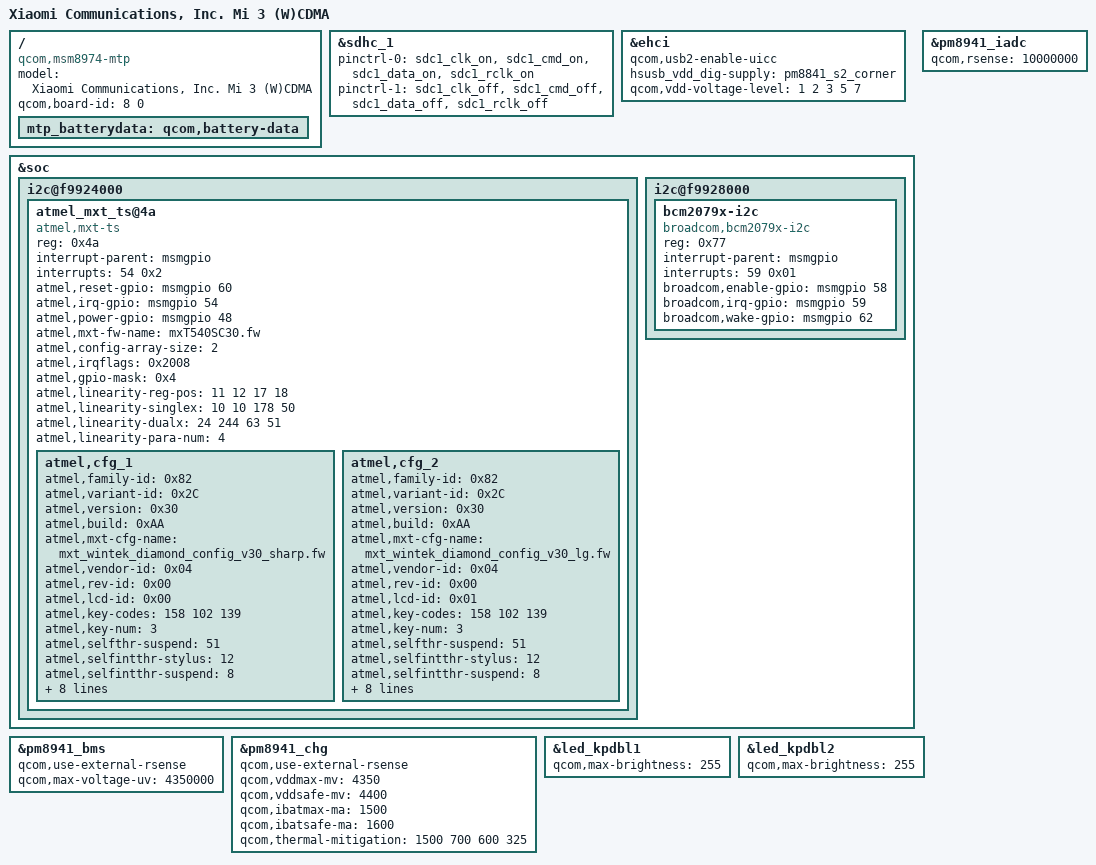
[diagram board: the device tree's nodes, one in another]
/* Copyright (c) 2013-2014, The Linux Foundation. All rights reserved.
 *
 * This program is free software; you can redistribute it and/or modify
 * it under the terms of the GNU General Public License version 2 and
 * only version 2 as published by the Free Software Foundation.
 *
 * This program is distributed in the hope that it will be useful,
 * but WITHOUT ANY WARRANTY; without even the implied warranty of
 * MERCHANTABILITY or FITNESS FOR A PARTICULAR PURPOSE.  See the
 * GNU General Public License for more details.
 */

/dts-v1/;

#include "msm8974pro-ab-pm8941.dtsi"
#include "msm8974-mtp.dtsi"
#include "msm8974-camera-sensor-mtp-xiaomi.dtsi"

/ {
	model = "Xiaomi Communications, Inc. Mi 3 (W)CDMA";
	compatible = "qcom,msm8974-mtp", "qcom,msm8974", "qcom,mtp";
	qcom,board-id = <8 0>;
};

&sdhc_1 {
	pinctrl-0 = <&sdc1_clk_on &sdc1_cmd_on &sdc1_data_on &sdc1_rclk_on>;
	pinctrl-1 = <&sdc1_clk_off &sdc1_cmd_off &sdc1_data_off &sdc1_rclk_off>;
};

&ehci {
	status = "ok";
	qcom,usb2-enable-uicc;
	hsusb_vdd_dig-supply = <&pm8841_s2_corner>;
	qcom,vdd-voltage-level = <1 2 3 5 7>;
};

&soc {

	i2c@f9924000 {
		atmel_mxt_ts@4a {
			compatible = "atmel,mxt-ts";
			reg = <0x4a>;
			interrupt-parent = <&msmgpio>;
			interrupts = <54 0x2>;
			atmel,reset-gpio = <&msmgpio 60 0x00>;
			atmel,irq-gpio = <&msmgpio 54 0x2008>;
			atmel,power-gpio = <&msmgpio 48 0x00>;
			atmel,mxt-fw-name = "mxT540SC30.fw";
			atmel,config-array-size = <2>;
			atmel,irqflags = <0x2008>;
			atmel,gpio-mask = <0x4>;
            atmel,linearity-reg-pos = <11 12 17 18>;
            atmel,linearity-singlex = <10 10 178 50>;
            atmel,linearity-dualx = <24 244 63 51>;
            atmel,linearity-para-num = <4>;
			atmel,cfg_1 {
				atmel,family-id = <0x82>;
				atmel,variant-id = <0x2C>;
				atmel,version = <0x30>;
				atmel,build = <0xAA>;
				atmel,mxt-cfg-name = "mxt_wintek_diamond_config_v30_sharp.fw";
				atmel,vendor-id = <0x04>;
				atmel,rev-id = <0x00>;
				atmel,lcd-id = <0x00>;
				atmel,key-codes = <158 102 139>;
				atmel,key-num = <3>;
                atmel,selfthr-suspend = <51>;
				atmel,selfintthr-stylus = <12>;
                atmel,selfintthr-suspend = <8>;
				atmel,t71-tchthr-pos = <22>;
				atmel,self-chgtime-min = <0>;
				atmel,self-chgtime-max = <0>;
				atmel,mult-intthr-sensitive = <12>;
				atmel,mult-intthr-not-sensitive = <20>;
				atmel,atchthr-sensitive = <6>;
				atmel,mult-tchthr-sensitive = <0x3C>;
				atmel,mult-tchthr-not-sensitive = <0x20>;
			};
			atmel,cfg_2 {
				atmel,family-id = <0x82>;
				atmel,variant-id = <0x2C>;
				atmel,version = <0x30>;
				atmel,build = <0xAA>;
				atmel,mxt-cfg-name = "mxt_wintek_diamond_config_v30_lg.fw";
				atmel,vendor-id = <0x04>;
				atmel,rev-id = <0x00>;
				atmel,lcd-id = <0x01>;
				atmel,key-codes = <158 102 139>;
				atmel,key-num = <3>;
                atmel,selfthr-suspend = <51>;
				atmel,selfintthr-stylus = <12>;
                atmel,selfintthr-suspend = <8>;
				atmel,t71-tchthr-pos = <22>;
				atmel,self-chgtime-min = <0>;
				atmel,self-chgtime-max = <0>;
				atmel,mult-intthr-sensitive = <12>;
				atmel,mult-intthr-not-sensitive = <20>;
				atmel,atchthr-sensitive = <6>;
				atmel,mult-tchthr-sensitive = <0x3C>;
				atmel,mult-tchthr-not-sensitive = <0x20>;
			};
		};
	};

	i2c@f9928000 {
		bcm2079x-i2c {
			compatible = "broadcom,bcm2079x-i2c";
			reg = <0x77>;
			interrupt-parent = <&msmgpio>;
			interrupts = <59 0x01>;
			broadcom,enable-gpio = <&msmgpio 58 0x00>;
			broadcom,irq-gpio = <&msmgpio 59 0x00>;
			broadcom,wake-gpio = <&msmgpio 62 0x00>;
		};
	};


};

&pm8941_bms {
	qcom,use-external-rsense;
	qcom,max-voltage-uv = <4350000>;
};

&pm8941_chg {
	qcom,use-external-rsense;
	qcom,vddmax-mv = <4350>;
	qcom,vddsafe-mv = <4400>;
	qcom,ibatmax-ma = <1500>;
	qcom,ibatsafe-ma = <1600>;
	qcom,thermal-mitigation = <1500 700 600 325>;
};

&pm8941_iadc {
	qcom,rsense = <10000000>;
};

&led_kpdbl1 {
    qcom,max-brightness = <255>;
};

&led_kpdbl2 {
    qcom,max-brightness = <255>;
};

/ {
	mtp_batterydata: qcom,battery-data {
		#include "batterydata-BM31-SDI-2980mAh.dtsi"
		#include "batterydata-BM31-SONY-2980mAh.dtsi"
		#include "batterydata-BM31-LG-2980mAh.dtsi"
	};
};
